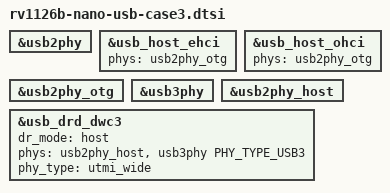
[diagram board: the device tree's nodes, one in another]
// SPDX-License-Identifier: (GPL-2.0+ OR MIT)
/*
 * Copyright (c) 2025 Guangzhou EASY EAI Technology Co., Ltd.
 */

//usb2phy_otg和usb2phy_host的父节点
&usb2phy {
	status = "okay";
};

/* USB2.0 HOST */
&usb_host_ehci {
	status = "okay";
	phys = <&usb2phy_otg>;
};

&usb_host_ohci {
	status = "okay";
	phys = <&usb2phy_otg>;
};

&usb2phy_otg {
	status = "okay";
};

/* Combined for USB3.0 HOST */
&usb3phy {
	status = "okay";
};

&usb2phy_host {
	status = "okay";
};

&usb_drd_dwc3 {
	status = "okay";
	dr_mode = "host";
	phys = <&usb2phy_host>, <&usb3phy PHY_TYPE_USB3>;
	phy-names = "usb2-phy", "usb3-phy";
	phy_type = "utmi_wide";
};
